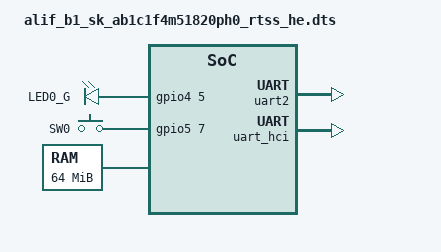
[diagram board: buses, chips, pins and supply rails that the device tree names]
/* Copyright (c) 2026 Alif Semiconductor
 *
 * SPDX-License-Identifier: Apache-2.0
 */

/dts-v1/;

#include <alif/balletto/b1/ab1c1f4m51820ph0.dtsi> /* change-1 */
#include "../common/ensemble-starterkit-b1-pinctrl.dtsi" /* change-2 */

/ {
	compatible = "arm,alif-b1-sk-ab1c1f4m51820ph0-rtss-he";   /* change-3 */
	#address-cells = <1>;
	#size-cells = <1>;

	
	chosen {
		zephyr,console = &uart2;
		zephyr,shell-uart = &uart2;
		zephyr,bt-hci = &alif_hci_uart;
		zephyr,hci-uart = &uart_hci;
		zephyr,uart-mcumgr = &uart2;
		zephyr,entropy = &rng;
	};

	aliases {
		led0 = &aled0;
		sw0 = &button0;
		watchdog0 = &wdog0;
	};

	leds {
		compatible = "gpio-leds";

		aled0: led_0 {
			gpios = <&gpio4 5 0>;
			label = "LED0_G";
		};
	};

	buttons {
		compatible = "gpio-keys";

		button0: button_0 {
			gpios = < &gpio5 7 0 >;
			label = "SW0";
		};
	};

	ext_flash_xip: memory@b0000000 {
		compatible = "zephyr,memory-region";
		reg = <0xb0000000 DT_SIZE_M(64)>;
		zephyr,memory-region = "OSPI0";
	};
};

&gpio4 {
	status = "okay";
};

&gpio5 {
	status = "okay";
};

&uart2 {
	status = "okay";
};

&uart_hci {
	clock-frequency = <160000000>;
	dmas = <&dma2 HCI_UART_DMA_RX_CH HCI_UART_DMA_RX_REQ>,
	       <&dma2 HCI_UART_DMA_TX_CH HCI_UART_DMA_TX_REQ>;
	dma-names = "rx", "tx";
	status = "okay";
};


&dma2 {
	status = "okay";
};

&mram_storage {
	partitions {
		compatible = "fixed-partitions";
		#address-cells = <1>;
		#size-cells = <1>;

		boot_partition: partition@0 {
			label = "mcuboot";
			reg = <0x00000000 DT_SIZE_K(64)>;
			read-only;
		};

		slot0_partition: partition@10000 {
			label = "image-0";
			reg = <0x00010000 DT_SIZE_K(843)>;
		};

		slot1_partition: partition@E2C00 {
			label = "image-1";
			reg = <0x000E2C00 DT_SIZE_K(843)>;
		};

		scratch_partition: partition@1B5800 {
			label = "image-scratch";
			reg = <0x001B5800 DT_SIZE_K(64)>;
		};

		storage_partition: partition@1C5800 {
			label = "storage";
			reg = <0x001C5800 DT_SIZE_K(10)>;
		};
	};
};
